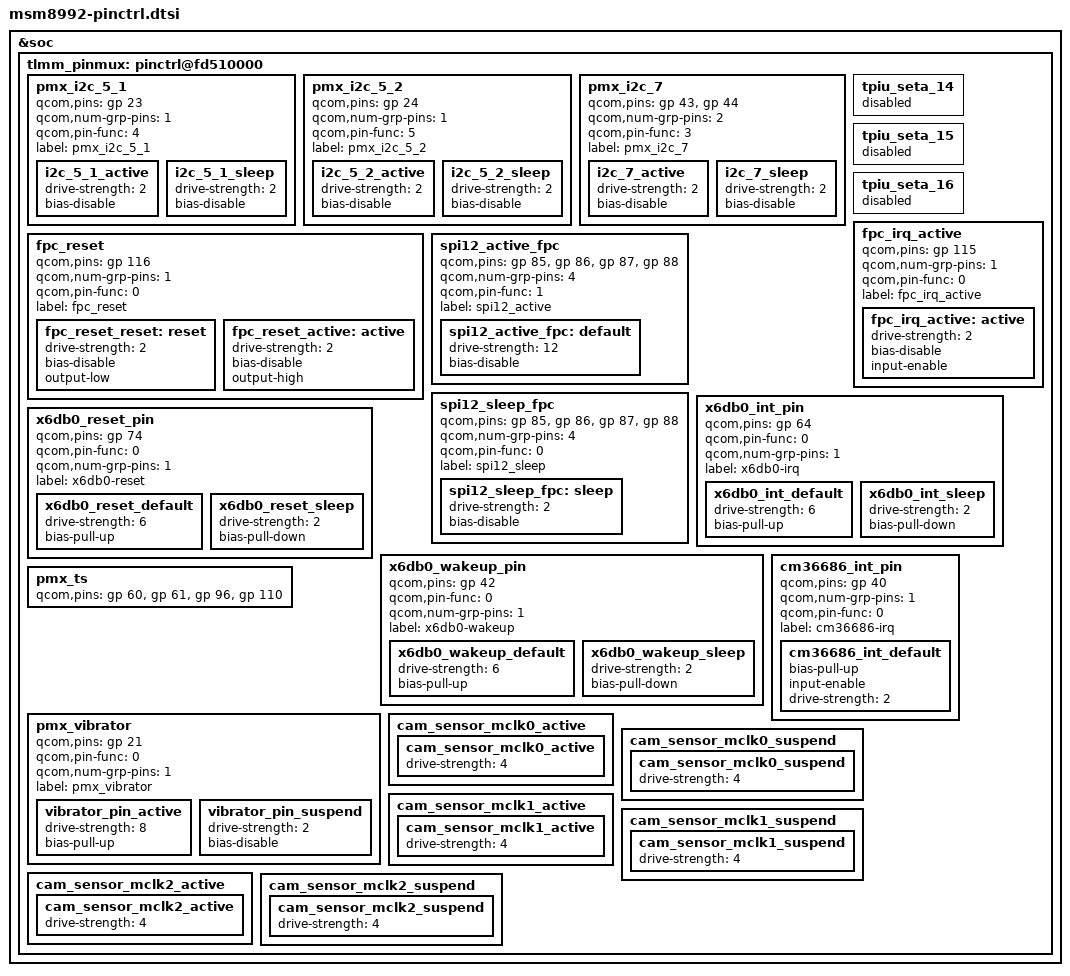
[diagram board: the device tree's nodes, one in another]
/* Copyright (c) 2013-2015, The Linux Foundation. All rights reserved.
 * Copyright (C) 2016 XiaoMi, Inc.
 * Modified by Ketut Putu Kumajaya, 2016
 *
 * This program is free software; you can redistribute it and/or modify
 * it under the terms of the GNU General Public License version 2 and
 * only version 2 as published by the Free Software Foundation.
 *
 * This program is distributed in the hope that it will be useful,
 * but WITHOUT ANY WARRANTY; without even the implied warranty of
 * MERCHANTABILITY or FITNESS FOR A PARTICULAR PURPOSE.  See the
 * GNU General Public License for more details.
 */

#include "../msm8992-pinctrl.dtsi"

&soc {
	tlmm_pinmux: pinctrl@fd510000 {
		pmx_i2c_5_1 {
			qcom,pins = <&gp 23>; /* SDA*/
			qcom,num-grp-pins = <1>;
			qcom,pin-func = <4>;
			label = "pmx_i2c_5_1";

			i2c_5_1_active: i2c_5_1_active {
				drive-strength = <2>;
				bias-disable;
			};

			i2c_5_1_sleep: i2c_5_1_sleep {
				drive-strength = <2>;
				bias-disable;
			};
		};

		pmx_i2c_5_2 {
			qcom,pins = <&gp 24>; /* SCL*/
			qcom,num-grp-pins = <1>;
			qcom,pin-func = <5>;
			label = "pmx_i2c_5_2";

			i2c_5_2_active: i2c_5_2_active {
				drive-strength = <2>;
				bias-disable;
			};

			i2c_5_2_sleep: i2c_5_2_sleep {
				drive-strength = <2>;
				bias-disable;
			};
		};

		pmx_i2c_7 {
			qcom,pins = <&gp 43>, <&gp 44>; /* SDA, SCL */
			qcom,num-grp-pins = <2>;
			qcom,pin-func = <3>;
			label = "pmx_i2c_7";

			i2c_7_active: i2c_7_active {
				drive-strength = <2>;
				bias-disable;
			};

			i2c_7_sleep: i2c_7_sleep {
				drive-strength = <2>;
				bias-disable;
			};
		};

		tpiu_seta_14 {
			status = "disabled";
		};

		tpiu_seta_15 {
			status = "disabled";
		};

		tpiu_seta_16 {
			status = "disabled";
		};

		fpc_reset {
			qcom,pins = <&gp 116>;
			qcom,num-grp-pins = <1>;
			qcom,pin-func = <0>;
			label = "fpc_reset";
			fpc_reset_reset: reset {
				drive-strength = <2>;
				bias-disable;
				output-low;
			};
			fpc_reset_active: active {
				drive-strength = <2>;
				bias-disable;
				output-high;
			};
		};

		fpc_irq_active {
			qcom,pins = <&gp 115>;
			qcom,num-grp-pins = <1>;
			qcom,pin-func = <0>;
			label = "fpc_irq_active";
			fpc_irq_active: active {
				drive-strength = <2>;
				bias-disable;
				input-enable;
			};
		};

		spi12_active_fpc {
			qcom,pins = <&gp 85>, <&gp 86>, <&gp 87>, <&gp 88>;
			qcom,num-grp-pins = <4>;
			qcom,pin-func = <1>;
			label = "spi12_active";
			spi12_active_fpc: default {
				drive-strength = <12>;
				bias-disable;
			};
		};

		spi12_sleep_fpc {
			qcom,pins = <&gp 85>, <&gp 86>, <&gp 87>, <&gp 88>;
			qcom,num-grp-pins = <4>;
			qcom,pin-func = <0>;
			label = "spi12_sleep";
			spi12_sleep_fpc: sleep {
				drive-strength = <2>;
				bias-disable;
			};
		};

		x6db0_int_pin {
			/* Gyroscope and accelerometer sensor combo */
			qcom,pins = <&gp 64>;
			qcom,pin-func = <0>;
			qcom,num-grp-pins = <1>;
			label = "x6db0-irq";
			x6db0_int_default: x6db0_int_default {
				drive-strength = <6>;
				bias-pull-up;
			};
			x6db0_int_sleep: x6db0_int_sleep {
				drive-strength = <2>;
				bias-pull-down;
			};
		};

		x6db0_reset_pin {
			/* Gyroscope and accelerometer sensor combo */
			qcom,pins = <&gp 74>;
			qcom,pin-func = <0>;
			qcom,num-grp-pins = <1>;
			label = "x6db0-reset";
			x6db0_reset_default: x6db0_reset_default {
				drive-strength = <6>;
				bias-pull-up;
			};
			x6db0_reset_sleep: x6db0_reset_sleep {
				drive-strength = <2>;
				bias-pull-down;
			};
		};

		x6db0_wakeup_pin {
			/* Gyroscope and accelerometer sensor combo */
			qcom,pins = <&gp 42>;
			qcom,pin-func = <0>;
			qcom,num-grp-pins = <1>;
			label = "x6db0-wakeup";
			x6db0_wakeup_default: x6db0_wakeup_default {
				drive-strength = <6>;
				bias-pull-up;
			};
			x6db0_wakeup_sleep: x6db0_wakeup_sleep {
				drive-strength = <2>;
				bias-pull-down;
			};
		};

		cm36686_int_pin {
			qcom,pins = <&gp 40>;
			qcom,num-grp-pins = <1>;
			qcom,pin-func = <0>;
			label = "cm36686-irq";
			cm36686_int_default: cm36686_int_default {
				bias-pull-up;
				input-enable;
				drive-strength = <2>;
			};
		};

		pmx_ts {
			qcom,pins = <&gp 60>, <&gp 61>, <&gp 96>, <&gp 110>;
		};

		pmx_vibrator {
			qcom,pins = <&gp 21>;
			qcom,pin-func = <0>;
			qcom,num-grp-pins = <1>;
			label = "pmx_vibrator";

			vibrator_pin_active: vibrator_pin_active {
				drive-strength = <8>;
				bias-pull-up;
			};

			vibrator_pin_suspend: vibrator_pin_suspend {
				drive-strength = <2>;
				bias-disable;
			};
		};

		cam_sensor_mclk0_active {
			cam_sensor_mclk0_active: cam_sensor_mclk0_active {
				drive-strength = <4>; /* 4 MA */
			};
		};

		cam_sensor_mclk0_suspend {
			cam_sensor_mclk0_suspend: cam_sensor_mclk0_suspend {
				drive-strength = <4>; /* 4 MA */
			};
		};

		cam_sensor_mclk1_active {
			cam_sensor_mclk1_active: cam_sensor_mclk1_active {
				drive-strength = <4>; /* 4 MA */
			};
		};

		cam_sensor_mclk1_suspend {
			cam_sensor_mclk1_suspend: cam_sensor_mclk1_suspend {
				drive-strength = <4>; /* 4 MA */
			};
		};

		cam_sensor_mclk2_active {
			cam_sensor_mclk2_active: cam_sensor_mclk2_active {
				drive-strength = <4>; /* 4 MA */
			};
		};

		cam_sensor_mclk2_suspend {
			cam_sensor_mclk2_suspend: cam_sensor_mclk2_suspend {
				drive-strength = <4>; /* 4 MA */
			};
		};
	};
};
